AUTOSAR XML (schema 4-3-0)
package /Impl_IOEXP_ARPkg
  swc implementation Impl_SWC_IOEXP_type: programming-language=C, sw-version=1.0.0, vendor-id=0, behavior=SWC_IOEXP_type_IB
    code-descriptors:
      code SRC: artifact-descriptors=autosar-engineering-object={short-label=EngObject, category=SWSRC}
    resource consumption ResourceConsumption
      memory section Mem_SWC_IOEXP_CODE: size=0, sw-addrmethod=CODE, symbol=CODE
package /Interface_IOEXP_ARPkg
  client server interface IF_IOExpIN_CDD
    operation CSOP_IOExpGetVal
      arg u8_CTDSW: type=uint8, direction=OUT, server-argument-impl-policy=USE-ARGUMENT-TYPE
      arg u8_TrunkHanSW: type=uint8, direction=OUT, server-argument-impl-policy=USE-ARGUMENT-TYPE
      arg u8_TailgateSW: type=uint8, direction=OUT, server-argument-impl-policy=USE-ARGUMENT-TYPE
  client server interface IF_IOExpOUT_CDD
    operation CSOP_IOExpSetVal
      arg u8_IVIRstCmd: type=uint8, direction=IN, server-argument-impl-policy=USE-ARGUMENT-TYPE
package /SWC_IOEXP_ARPkg
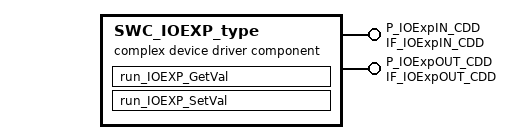
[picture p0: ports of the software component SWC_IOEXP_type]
  complex device driver sw component type SWC_IOEXP_type
    provide port P_IOExpIN_CDD: provided-interface=IF_IOExpIN_CDD
    provide port P_IOExpOUT_CDD: provided-interface=IF_IOExpOUT_CDD
    behavior SWC_IOEXP_type_IB: handle-termination-and-restart=NO-SUPPORT
      operation invoked event oie_P_IOExpIN_CDD_CSOP_IOExpGetVal: start-on-event=run_IOEXP_GetVal, operation=P_IOExpIN_CDD.CSOP_IOExpGetVal
      operation invoked event oie_P_IOExpOUT_CDD_CSOP_IOExpSetVal: start-on-event=run_IOEXP_SetVal, operation=P_IOExpOUT_CDD.CSOP_IOExpSetVal
      port-api-options:
        enable-take-address=false, indirect-api=false, port=P_IOExpIN_CDD
        enable-take-address=false, indirect-api=false, port=P_IOExpOUT_CDD
      runnable run_IOEXP_GetVal
      runnable run_IOEXP_SetVal
